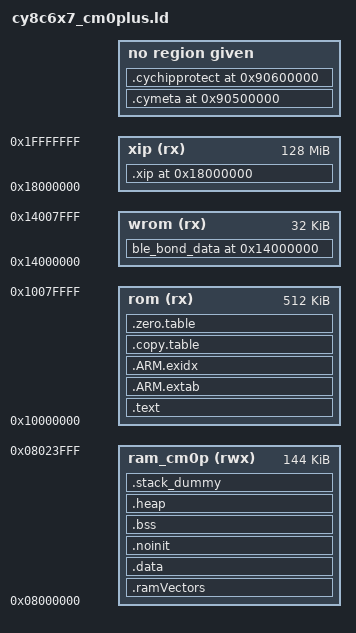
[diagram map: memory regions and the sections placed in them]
/***************************************************************************//**
* \file cy8c6x7_cm0plus.ld
* \version 1.0
*
* \brief Linker file for the GNU C compiler.
*
* \note The entry point location is fixed and starts at 0x10000000. The valid
* application image should be placed there.
*
* \note The linker files included with the PDL template projects must be generic
* and handle all common use cases. Your project may not use every section
* defined in the linker files. In that case you may see warnings during the
* build process. In your project, you can simply comment out or remove the
* relevant code in the linker file.
*
********************************************************************************
* \copyright
* Copyright 2016-2017, Cypress Semiconductor Corporation.  All rights reserved.
* You may use this file only in accordance with the license, terms, conditions,
* disclaimers, and limitations in the end user license agreement accompanying
* the software package with which this file was provided.
*******************************************************************************/

OUTPUT_FORMAT ("elf32-littlearm", "elf32-bigarm", "elf32-littlearm")
SEARCH_DIR(.)
GROUP(-lgcc -lc -lnosys)
ENTRY(Reset_Handler)


/* Force symbol to be entered in the output file as an undefined symbol. Doing
* this may, for example, trigger linking of additional modules from standard
* libraries. You may list several symbols for each EXTERN, and you may use
* EXTERN multiple times. This command has the same effect as the -u command-line
* option.
*/
EXTERN(Reset_Handler)
EXTERN(vectors)
EXTERN(ram_vectors)
EXTERN(cychipprotect)
EXTERN(cymeta)

/* Flash */
__cy_memory_0_start    = 0x10000000;
__cy_memory_0_length   = 0x00100000;
__cy_memory_0_row_size = 0x200;

/* Working Flash */
__cy_memory_1_start    = 0x14000000;
__cy_memory_1_length   = 0x8000;
__cy_memory_1_row_size = 0x200;

/* XIP */
__cy_memory_2_start    = 0x18000000;
__cy_memory_2_length   = 0x08000000;
__cy_memory_2_row_size = 0x200;


/* Linker script to configure memory regions. */
MEMORY
{
    rom         (rx)  : ORIGIN = 0x10000000, LENGTH = 0x00080000
    wrom        (rx)  : ORIGIN = 0x14000000, LENGTH = 0x8000
    xip         (rx)  : ORIGIN = 0x18000000, LENGTH = 0x08000000
    ram_cm0p    (rwx) : ORIGIN = 0x08000000, LENGTH = 0x00024000
}


/* Library configurations */
GROUP(libgcc.a libc.a libm.a libnosys.a)

/* Linker script to place sections and symbol values. Should be used together
 * with other linker script that defines memory regions FLASH and RAM.
 * It references following symbols, which must be defined in code:
 *   Reset_Handler : Entry of reset handler
 *
 * It defines following symbols, which code can use without definition:
 *   __exidx_start
 *   __exidx_end
 *   __copy_table_start__
 *   __copy_table_end__
 *   __zero_table_start__
 *   __zero_table_end__
 *   __etext
 *   __data_start__
 *   __preinit_array_start
 *   __preinit_array_end
 *   __init_array_start
 *   __init_array_end
 *   __fini_array_start
 *   __fini_array_end
 *   __data_end__
 *   __bss_start__
 *   __bss_end__
 *   __end__
 *   end
 *   __HeapLimit
 *   __StackLimit
 *   __StackTop
 *   __stack
 *   __Vectors_End
 *   __Vectors_Size
 */
ENTRY(Reset_Handler)

SECTIONS
{
    .text :
    {
        /* Cortex-M0+ ROM vector table */
        . = ALIGN(4);
        __Vectors = . ;
        KEEP(*(.vectors))
        . = ALIGN(4);
        __Vectors_End = .;
        __Vectors_Size = __Vectors_End - __Vectors;
        __end__ = .;

        . = ALIGN(4);
        *(.text*)

        KEEP(*(.init))
        KEEP(*(.fini))

        /* .ctors */
        *crtbegin.o(.ctors)
        *crtbegin?.o(.ctors)
        *(EXCLUDE_FILE(*crtend?.o *crtend.o) .ctors)
        *(SORT(.ctors.*))
        *(.ctors)

        /* .dtors */
        *crtbegin.o(.dtors)
        *crtbegin?.o(.dtors)
        *(EXCLUDE_FILE(*crtend?.o *crtend.o) .dtors)
        *(SORT(.dtors.*))
        *(.dtors)

        /* Read-only code (constants). */
        *(.rodata .rodata.* .constdata .constdata.* .conststring .conststring.*)

        KEEP(*(.eh_frame*))
    } > rom


    .ARM.extab :
    {
        *(.ARM.extab* .gnu.linkonce.armextab.*)
    } > rom

    __exidx_start = .;

    .ARM.exidx :
    {
        *(.ARM.exidx* .gnu.linkonce.armexidx.*)
    } > rom
    __exidx_end = .;


    /* To copy multiple ROM to RAM sections,
     * uncomment .copy.table section and,
     * define __STARTUP_COPY_MULTIPLE in startup_psoc6ble_cm0plus.S */
    .copy.table :
    {
        . = ALIGN(4);
        __copy_table_start__ = .;

        /* Copy interrupt vectors from flash to RAM */
        LONG (__Vectors)                                    /* From */
        LONG (__ram_vectors_start__)                        /* To   */
        LONG (__Vectors_End - __Vectors)                    /* Size */

        /* Copy data section to RAM */
        LONG (__etext)                                      /* From */
        LONG (__data_start__)                               /* To   */
        LONG (__data_end__ - __data_start__)                /* Size */

        __copy_table_end__ = .;
    } > rom



    /* To clear multiple BSS sections,
     * uncomment .zero.table section and,
     * define __STARTUP_CLEAR_BSS_MULTIPLE in startup_psoc6ble_cm0plus.S */
    .zero.table :
    {
        . = ALIGN(4);
        __zero_table_start__ = .;
        LONG (__bss_start__)
        LONG (__bss_end__ - __bss_start__)
        __zero_table_end__ = .;
    } > rom

    __etext =  . ;


    .ramVectors (NOLOAD) : ALIGN(8)
    {
        __ram_vectors_start__ = .;
        KEEP(*(.ram_vectors))
        __ram_vectors_end__   = .;
    } > ram_cm0p


    .data __ram_vectors_end__ : AT (__etext)
    {
        __data_start__ = .;

        *(vtable)
        *(.data*)

        . = ALIGN(4);
        /* preinit data */
        PROVIDE_HIDDEN (__preinit_array_start = .);
        KEEP(*(.preinit_array))
        PROVIDE_HIDDEN (__preinit_array_end = .);

        . = ALIGN(4);
        /* init data */
        PROVIDE_HIDDEN (__init_array_start = .);
        KEEP(*(SORT(.init_array.*)))
        KEEP(*(.init_array))
        PROVIDE_HIDDEN (__init_array_end = .);


        . = ALIGN(4);
        /* finit data */
        PROVIDE_HIDDEN (__fini_array_start = .);
        KEEP(*(SORT(.fini_array.*)))
        KEEP(*(.fini_array))
        PROVIDE_HIDDEN (__fini_array_end = .);

        KEEP(*(.jcr*))
        . = ALIGN(4);

        __data_end__ = .;

    } > ram_cm0p


    /* Place variables in the section that should not be initialized during the
    *  device startup.
    */
    .noinit (NOLOAD) : ALIGN(8)
    {
      KEEP(*(.noinit))
    } > ram_cm0p


    /* The uninitialized global or static variables are placed in this section.
    *
    * The NOLOAD attribute tells linker that .bss section does not consume
    * any space in the image. The NOLOAD attribute changes the .bss type to
    * NOBITS, and that  makes linker to A) not allocate section in memory, and
    * A) put information to clear the section with all zeros during application
    * loading.
    *
    * Without the NOLOAD attribute, the .bss section might get PROGBITS type.
    * This  makes linker to A) allocate zeroed section in memory, and B) copy
    * this section to RAM during application loading.
    */
    .bss (NOLOAD):
    {
        . = ALIGN(4);
        __bss_start__ = .;
        *(.bss*)
        *(COMMON)
        . = ALIGN(4);
        __bss_end__ = .;
    } > ram_cm0p


    .heap (NOLOAD):
    {
        __HeapBase = .;
        __end__ = .;
        end = __end__;
        KEEP(*(.heap*))
        __HeapLimit = .;
    } > ram_cm0p

    /* .stack_dummy section doesn't contains any symbols. It is only
     * used for linker to calculate size of stack sections, and assign
     * values to stack symbols later */
    .stack_dummy (NOLOAD):
    {
        KEEP(*(.stack*))
    } > ram_cm0p

    /* Set stack top to end of RAM, and stack limit move down by
     * size of stack_dummy section */
    __StackTop = ORIGIN(ram_cm0p) + LENGTH(ram_cm0p);
    __StackLimit = __StackTop - SIZEOF(.stack_dummy);
    PROVIDE(__stack = __StackTop);

    /* Check if data + heap + stack exceeds RAM limit */
    ASSERT(__StackLimit >= __HeapLimit, "region RAM overflowed with stack")


    /* The section is used for BLE bonding data storage. */
    ble_bond_data 0x14000000 :
    {
        __ble_bond_data_start = . ;
        KEEP(*(.ble_bond_data))
        __ble_bond_data_end = . ;
    } > wrom


    /* Places the code in the Execute in Place (XIP) section. See the smif driver
    *  documentation for details.
    */
    .xip 0x18000000 :
    {
        . = ALIGN(4);
        __xip_data_start = . ;
        KEEP(*(.xip))
        __xip_data_end = . ;
    } > xip

    /* These sections are used for additional metadata (silicon revision,
    *  Silicon/JTAG ID, etc.) storage.
    */
    .cymeta         0x90500000 : { KEEP(*(.cymeta)) } :NONE
    .cychipprotect  0x90600000 : { KEEP(*(.cychipprotect)) } :NONE
}


/* EOF */
